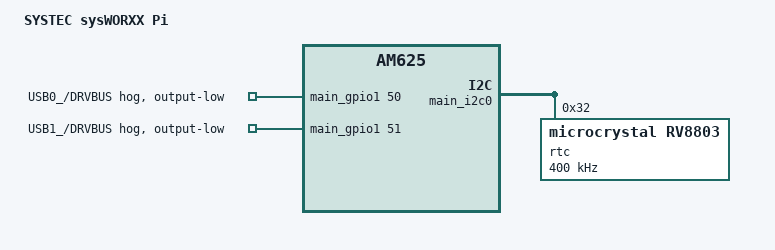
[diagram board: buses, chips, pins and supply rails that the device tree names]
/*
 * Copyright (C) 2023 SYSTEC electronic AG, All Rights Reserved
 *
 * This program is free software; you can redistribute it and/or modify
 * it under the terms of the GNU General Public License version 2 as
 * published by the Free Software Foundation.
 */
/dts-v1/;

#include "k3-am625.dtsi"
#include "k3-am625-systec-pi-pinmux-0.dtsi"
#include "k3-am625-systec-pi-common.dtsi"

/ {
	model = "SYSTEC sysWORXX Pi";
	compatible = "systec,pi,rev0", "systec,pi", "ti,am625";

	aliases {
		rtc0 = &rtc;
		rtc1 = &wkup_rtc0;
	};
};

// I2C0_MAIN
&main_i2c0 {
	/* RTC */
	rtc: rv8803@32 {
		clock-frequency = <400000>;
		compatible = "microcrystal,rv8803";
		reg = <0x32>;
	};
};

&main_gpio0 {
	pinctrl-names = "default";
	pinctrl-0 = <&gpio0_pins_default>;
	gpio-line-names      =
		"GPIO0_0",  "GPIO0_1",       "GPIO0_2",    "GPIO0_3",   // 0
		"GPIO0_4",  "WLAN_/DISABLE", "BT_REG_ON",  "GPIO0_7",   // 4
		"GPIO0_8",  "GPIO0_9",       "GPIO0_10",   "LED_BL",    // 8
		"LED_RD",   "GPIO0_13",      "LED_GN",     "BM0",       // 12
		"BM1",      "BM2",           "BM3",        "",          // 16
		"",         "",              "",           "",          // 20
		"",         "",              "",           "",          // 24
		"",         "",              "",           "EMMC_/RST", // 28
		"",         "GPIO0_33",      "GPIO0_34",   "GPIO0_35",  // 32
		"USB1_/ID", "GPIO0_37",      "PWRGD",      "",          // 36
		"GPIO0_40", "GPIO0_41",      "RGMII_/INT", "GPIO0_43",  // 40
		"GPIO0_44", "",              "",           "",          // 44
		"",         "",              "",           "",          // 48
		"",         "",              "",           "",          // 52
		"",         "",              "",           "",          // 56
		"",         "",              "",           "",          // 60
		"",         "",              "",           "",          // 64
		"",         "",              "",           "GPIO0_71",  // 68
		"GPIO0_72", "",              "",           "",          // 72
		"",         "",              "",           "",          // 76
		"",         "",              "",           "",          // 80
		"",         "RGMII_MIO",     "RGMII_MDC",  "",          // 84
		"",         "",              "",           "";          // 88
};

&main_gpio1 {
	pinctrl-names = "default";
	pinctrl-0 = <&gpio1_pins_default>;
	gpio-line-names =
		"",           "",           "",             "",             // 0
		"",           "",           "",             "",             // 4
		"HDMI_/RST",  "GPIO1_9",    "",             "",             // 8
		"",           "HDMI_/INT",  "VPP_LDO_EN",   "ETH0_/RST",    // 12
		"USB1_/OC",   "USB0_/OC",   "USB1_/INT",    "USB1_DFP/UFP", // 16
		"SERVICE_RX", "SERVICE_TX", "GPIO1_23",     "GPIO1_22",     // 20
		"GPIO1_24",   "GPIO1_25",   "I2C0_SCL",     "I2C0_SDA",     // 24
		"GPIO1_28",   "ETH1_/RST",  "",             "",             // 28
		"",           "",           "",             "",             // 32
		"",           "",           "",             "",             // 36
		"",           "",           "",             "",             // 40
		"",           "",           "",             "",             // 44
		"",           "SW_SD-Card", "USB0_/DRVBUS", "USB1_/DRVBUS", // 48
		"",           "",           "",             "",             // 52
		"",           "",           "",             "",             // 56
		"",           "",           "",             "",             // 60
		"",           "",           "",             "",             // 64
		"",           "",           "",             "GPIO0_71",     // 68
		"GPIO0_72",   "",           "",             "",             // 72
		"",           "",           "",             "",             // 76
		"",           "",           "",             "",             // 80
		"",           "",           "",             "",             // 84
		"",           "",           "",             "";             // 88

	usb0-drvvbus-hog {
		gpio-hog;
		gpios = <50 GPIO_ACTIVE_HIGH>;
		output-low;
		line-name = "USB0_/DRVBUS";
	};

	usb1-drvvbus-hog {
		gpio-hog;
		gpios = <51 GPIO_ACTIVE_HIGH>;
		output-low;
		line-name = "USB1_/DRVBUS";
	};
};

&mcu_gpio0 {
	pinctrl-names = "default";
	pinctrl-0 = <&mcugpio1_pins_default>;
	gpio-line-names =
		"",       "",             "",             "",       // 0
		"",       "BT_RX",        "BT_TX",        "BT_CTS", // 4
		"BT_RTS", "",             "",             "",       // 8
		"",       "MCU_GPIO0_13", "MCU_GPIO0_14", "",       // 12
		"",       "",         	  "",             "",       // 16
		"",       "",             "",             "";       // 20
};
